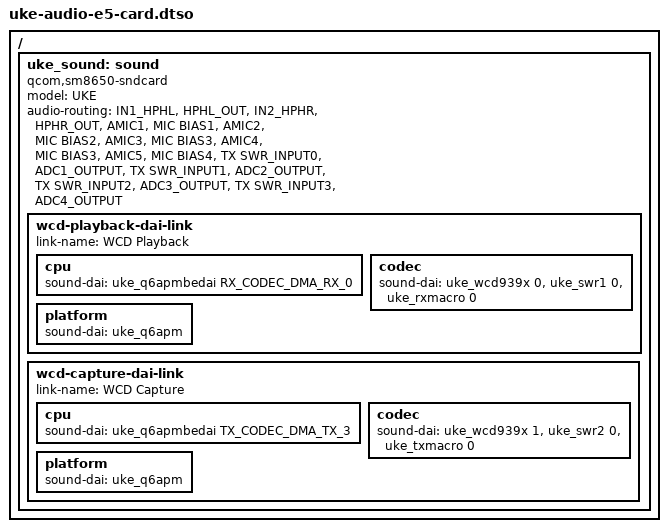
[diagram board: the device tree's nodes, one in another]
// SPDX-License-Identifier: BSD-3-Clause
/*
 * uke-audio-e5-card.dtso — tarjeta (machine driver) de la uke: `sc8280xp.c` con compat qcom,sm8650-sndcard.
 * ESBOZO DE E0 (18-oct-2026): compila y se aplica con fdtoverlay sobre el DT vivo, NO probado en la tablet.
 *
 * Requiere e2, e3, e4 y e5-codec (usa &uke_q6apm, &uke_q6apmbedai, &uke_wcd939x, &uke_swr1/2, &uke_rxmacro/txmacro).
 * Se aplica el ULTIMO: al aparecer el nodo, el platform driver `snd-soc-sc8280xp` sondea y pide el firmware
 *     /lib/firmware/qcom/sm8650/UKE-tplg.bin
 * (nombre = qcom/<driver_name>/<card->name>-tplg.bin, topology.c:1320; driver_name = "sm8650" del compat,
 * card->name = `model`). Si ese fichero no esta, sondeo fallido con error en dmesg (inocuo).
 *
 * Solo enlaces que la uke PUEDE tener hoy (piezas 100 % mainline, etapas E5/E6):
 *   - WCD Playback : RX_CODEC_DMA_RX_0 -> rx-macro -> SWR RX -> WCD9395   (E6; sin jack: a "ninguna parte")
 *   - WCD Capture  : TX_CODEC_DMA_TX_3 <- tx-macro <- SWR TX <- WCD9395   (E5; AMIC del WCD + DMIC por SWR)
 * Fuera a proposito: WSA (no hay), TDM1 de los 4 altavoces FS19xx (E7: falta soporte TDM en audioreach.c y los
 * parametros salen del ACDB `Forte`), DisplayPort, USB audio, BT SLIMbus, y el enlace VA de los DMIC digitales
 * (pines por resolver). El enlace VA seria:
 *     va-capture-dai-link { link-name = "VA Capture";
 *         cpu { sound-dai = <&uke_q6apmbedai VA_CODEC_DMA_TX_0>; };
 *         codec { sound-dai = <&uke_vamacro 0>; };
 *         platform { sound-dai = <&uke_q6apm>; }; };
 *
 * audio-routing: igual que sm8650-qrd.dts sin las lineas de WSA (SpkrLeft/SpkrRight). El vendor cuelga los DMIC
 * de MIC BIAS1/3 del WCD (qcom,audio-routing del DT vivo, "TX DMIC0 .. MIC BIAS3"): INFERIDO, sin medir.
 */
/dts-v1/;
/plugin/;

#include <dt-bindings/sound/qcom,q6dsp-lpass-ports.h>

/ {
	fragment@0 {
		target-path = "/";

		__overlay__ {
			uke_sound: sound {
				compatible = "qcom,sm8650-sndcard", "qcom,sm8450-sndcard";
				model = "UKE";
				audio-routing = "IN1_HPHL", "HPHL_OUT",
						"IN2_HPHR", "HPHR_OUT",
						"AMIC1", "MIC BIAS1",
						"AMIC2", "MIC BIAS2",
						"AMIC3", "MIC BIAS3",
						"AMIC4", "MIC BIAS3",
						"AMIC5", "MIC BIAS4",
						"TX SWR_INPUT0", "ADC1_OUTPUT",
						"TX SWR_INPUT1", "ADC2_OUTPUT",
						"TX SWR_INPUT2", "ADC3_OUTPUT",
						"TX SWR_INPUT3", "ADC4_OUTPUT";

				wcd-playback-dai-link {
					link-name = "WCD Playback";

					cpu {
						sound-dai = <&uke_q6apmbedai RX_CODEC_DMA_RX_0>;
					};

					codec {
						sound-dai = <&uke_wcd939x 0>, <&uke_swr1 0>, <&uke_rxmacro 0>;
					};

					platform {
						sound-dai = <&uke_q6apm>;
					};
				};

				wcd-capture-dai-link {
					link-name = "WCD Capture";

					cpu {
						sound-dai = <&uke_q6apmbedai TX_CODEC_DMA_TX_3>;
					};

					codec {
						sound-dai = <&uke_wcd939x 1>, <&uke_swr2 0>, <&uke_txmacro 0>;
					};

					platform {
						sound-dai = <&uke_q6apm>;
					};
				};
			};
		};
	};
};
